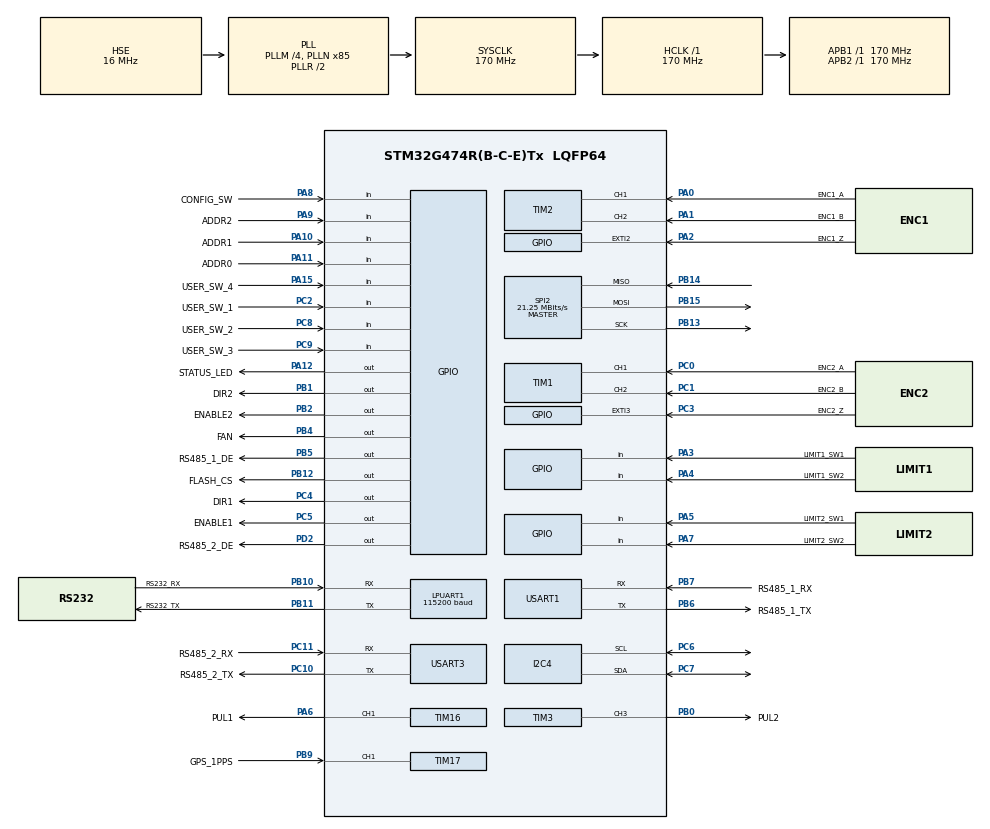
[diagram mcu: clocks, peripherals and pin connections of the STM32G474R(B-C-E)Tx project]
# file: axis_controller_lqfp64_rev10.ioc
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I2C4.Timing=0x40B285C2
LPUART1.BaudRate=115200
LPUART1.VirtualMode-Asynchronous=VM_ASYNC
Mcu.Family=STM32G4
Mcu.Name=STM32G474R(B-C-E)Tx
Mcu.Package=LQFP64
NVIC.EXTI2_IRQn=true\:0\:0\:false\:false\:true\:true\:true\:true
NVIC.EXTI3_IRQn=true\:0\:0\:false\:false\:true\:true\:true\:true
NVIC.I2C4_EV_IRQn=true\:0\:0\:false\:false\:true\:true\:true\:true
NVIC.LPUART1_IRQn=true\:0\:0\:false\:false\:true\:true\:true\:true
NVIC.PriorityGroup=NVIC_PRIORITYGROUP_4
NVIC.SPI2_IRQn=true\:0\:0\:false\:false\:true\:true\:true\:true
NVIC.TIM1_CC_IRQn=true\:0\:0\:false\:false\:true\:true\:true\:true
NVIC.TIM1_TRG_COM_TIM17_IRQn=true\:0\:0\:false\:false\:true\:true\:true\:true
NVIC.TIM1_UP_TIM16_IRQn=true\:0\:0\:false\:false\:true\:true\:true\:true
NVIC.TIM2_IRQn=true\:0\:0\:false\:false\:true\:true\:true\:true
NVIC.TIM3_IRQn=true\:0\:0\:false\:false\:true\:true\:true\:true
NVIC.USART1_IRQn=true\:0\:0\:false\:false\:true\:true\:true\:true
NVIC.USART3_IRQn=true\:0\:0\:false\:false\:true\:true\:true\:true
PA0.GPIO_Label=ENC1_A
PA0.Signal=S_TIM2_CH1
PA1.GPIO_Label=ENC1_B
PA1.Signal=S_TIM2_CH2
PA10.GPIO_Label=ADDR1
PA10.GPIO_PuPd=GPIO_PULLUP
PA10.Signal=GPIO_Input
PA11.GPIO_Label=ADDR0
PA11.GPIO_PuPd=GPIO_PULLUP
PA11.Signal=GPIO_Input
PA12.GPIO_Label=STATUS_LED
PA12.Signal=GPIO_Output
PA13.Mode=Trace_Asynchronous_SW
PA13.Signal=SYS_JTMS-SWDIO
PA14.Mode=Trace_Asynchronous_SW
PA14.Signal=SYS_JTCK-SWCLK
PA15.GPIO_Label=USER_SW_4
PA15.GPIO_PuPd=GPIO_PULLUP
PA15.Signal=GPIO_Input
PA2.GPIO_Label=ENC1_Z
PA2.GPIO_PuPd=GPIO_PULLUP
PA2.Signal=GPXTI2
PA3.GPIO_Label=LIMIT1_SW1
PA3.GPIO_PuPd=GPIO_PULLUP
PA3.Signal=GPIO_Input
PA4.GPIO_Label=LIMIT1_SW2
PA4.GPIO_PuPd=GPIO_PULLUP
PA4.Signal=GPIO_Input
PA5.GPIO_Label=LIMIT2_SW1
PA5.GPIO_PuPd=GPIO_PULLUP
PA5.Signal=GPIO_Input
PA6.GPIO_Label=PUL1
PA6.Signal=S_TIM16_CH1
PA7.GPIO_Label=LIMIT2_SW2
PA7.GPIO_PuPd=GPIO_PULLUP
PA7.Signal=GPIO_Input
PA8.GPIO_Label=CONFIG_SW
PA8.GPIO_PuPd=GPIO_PULLUP
PA8.Signal=GPIO_Input
PA9.GPIO_Label=ADDR2
PA9.GPIO_PuPd=GPIO_PULLUP
PA9.Signal=GPIO_Input
PB0.GPIO_Label=PUL2
PB0.Signal=S_TIM3_CH3
PB1.GPIO_Label=DIR2
PB1.Signal=GPIO_Output
PB10.GPIO_Label=RS232_RX
PB10.Mode=Asynchronous
PB10.Signal=LPUART1_RX
PB11.GPIO_Label=RS232_TX
PB11.Mode=Asynchronous
PB11.Signal=LPUART1_TX
PB12.GPIO_Label=FLASH_CS
PB12.GPIO_ModeDefaultOutputPP=GPIO_MODE_OUTPUT_PP
PB12.GPIO_Speed=GPIO_SPEED_FREQ_HIGH
PB12.Signal=GPIO_Output
PB13.Mode=Full_Duplex_Master
PB13.Signal=SPI2_SCK
PB14.Mode=Full_Duplex_Master
PB14.Signal=SPI2_MISO
PB15.Mode=Full_Duplex_Master
PB15.Signal=SPI2_MOSI
PB2.GPIO_Label=ENABLE2
PB2.Signal=GPIO_Output
PB3.Mode=Trace_Asynchronous_SW
PB3.Signal=SYS_JTDO-SWO
PB4.GPIO_Label=FAN
PB4.Signal=GPIO_Output
PB5.GPIO_Label=RS485_1_DE
PB5.Signal=GPIO_Output
PB6.GPIO_Label=RS485_1_TX
PB6.Mode=Asynchronous
PB6.Signal=USART1_TX
PB7.GPIO_Label=RS485_1_RX
PB7.Mode=Asynchronous
PB7.Signal=USART1_RX
PB9.GPIO_Label=GPS_1PPS
PB9.Signal=S_TIM17_CH1
PC0.GPIO_Label=ENC2_A
PC0.Signal=S_TIM1_CH1
PC1.GPIO_Label=ENC2_B
PC1.Signal=S_TIM1_CH2
PC10.GPIO_Label=RS485_2_TX
PC10.Mode=Asynchronous
PC10.Signal=USART3_TX
PC11.GPIO_Label=RS485_2_RX
PC11.Mode=Asynchronous
PC11.Signal=USART3_RX
PC2.GPIO_Label=USER_SW_1
PC2.GPIO_PuPd=GPIO_PULLUP
PC2.Signal=GPIO_Input
PC3.GPIO_Label=ENC2_Z
PC3.GPIO_PuPd=GPIO_PULLUP
PC3.Signal=GPXTI3
PC4.GPIO_Label=DIR1
PC4.Signal=GPIO_Output
PC5.GPIO_Label=ENABLE1
PC5.Signal=GPIO_Output
PC6.Mode=I2C
PC6.Signal=I2C4_SCL
PC7.Mode=I2C
PC7.Signal=I2C4_SDA
PC8.GPIO_Label=USER_SW_2
PC8.GPIO_PuPd=GPIO_PULLUP
PC8.Signal=GPIO_Input
PC9.GPIO_Label=USER_SW_3
PC9.GPIO_PuPd=GPIO_PULLUP
PC9.Signal=GPIO_Input
PD2.GPIO_Label=RS485_2_DE
PD2.Signal=GPIO_Output
PF0-OSC_IN.Mode=HSE-External-Oscillator
PF0-OSC_IN.Signal=RCC_OSC_IN
PF1-OSC_OUT.Mode=HSE-External-Oscillator
PF1-OSC_OUT.Signal=RCC_OSC_OUT
ProjectManager.HeapSize=0x800
ProjectManager.StackSize=0x800
ProjectManager.TargetToolchain=Makefile
RCC.ADC12Freq_Value=170000000
RCC.ADC345Freq_Value=170000000
RCC.AHBFreq_Value=170000000
RCC.APB1Freq_Value=170000000
RCC.APB1TimFreq_Value=170000000
RCC.APB2Freq_Value=170000000
RCC.APB2TimFreq_Value=170000000
RCC.CortexFreq_Value=170000000
RCC.EXTERNAL_CLOCK_VALUE=12288000
RCC.HCLKFreq_Value=170000000
RCC.HSE_VALUE=16000000
RCC.HSI48_VALUE=48000000
RCC.HSI_VALUE=16000000
RCC.LSE_VALUE=32768
RCC.PLLM=RCC_PLLM_DIV4
RCC.PLLN=85
RCC.PLLSourceVirtual=RCC_PLLSOURCE_HSE
RCC.SYSCLKFreq_VALUE=170000000
RCC.SYSCLKSource=RCC_SYSCLKSOURCE_PLLCLK
RCC.USBFreq_Value=170000000
RCC.VCOOutputFreq_Value=340000000
SH.S_TIM16_CH1.0=TIM16_CH1,PWM Generation1 CH1
SH.S_TIM17_CH1.0=TIM17_CH1,Input_Capture1_from_TI1
SH.S_TIM1_CH1.0=TIM1_CH1,Encoder_Interface
SH.S_TIM1_CH2.0=TIM1_CH2,Encoder_Interface
SH.S_TIM2_CH1.0=TIM2_CH1,Encoder_Interface
SH.S_TIM2_CH2.0=TIM2_CH2,Encoder_Interface
SH.S_TIM3_CH3.0=TIM3_CH3,PWM Generation3 CH3
SPI2.BaudRatePrescaler=SPI_BAUDRATEPRESCALER_8
SPI2.CLKPhase=SPI_PHASE_1EDGE
SPI2.CLKPolarity=SPI_POLARITY_LOW
SPI2.CalculateBaudRate=21.25 MBits/s
SPI2.DataSize=SPI_DATASIZE_8BIT
SPI2.Direction=SPI_DIRECTION_2LINES
SPI2.FirstBit=SPI_FIRSTBIT_MSB
SPI2.Mode=SPI_MODE_MASTER
SPI2.NSS=SPI_NSS_SOFT
SPI2.VirtualMode-Full_Duplex_Master=VM_MASTER
SPI2.VirtualType=VM_MASTER
TIM1.EncoderMode=TIM_ENCODERMODE_TI12
TIM1.IC1Filter=6
TIM1.IC2Filter=6
TIM16.AutoReloadPreload=TIM_AUTORELOAD_PRELOAD_ENABLE
TIM16.Channel=TIM_CHANNEL_1
TIM16.PeriodNoDither=999
TIM16.Prescaler=16
TIM16.PulseNoDither_1=500
TIM17.Channel=TIM_CHANNEL_1
TIM2.EncoderMode=TIM_ENCODERMODE_TI12
TIM2.IC1Filter=6
TIM2.IC2Filter=6
TIM3.AutoReloadPreload=TIM_AUTORELOAD_PRELOAD_ENABLE
TIM3.Channel-PWM\ Generation3\ CH3=TIM_CHANNEL_3
TIM3.PeriodNoDither=999
TIM3.Prescaler=16
TIM3.PulseNoDither_3=500
USART1.VirtualMode-Asynchronous=VM_ASYNC
USART3.VirtualMode-Asynchronous=VM_ASYNC
VP_SYS_VS_DBSignals.Mode=DisableDeadBatterySignals
VP_TIM16_VS_ClockSourceINT.Mode=Enable_Timer
VP_TIM17_VS_ClockSourceINT.Mode=Enable_Timer
board=custom

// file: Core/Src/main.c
/* USER CODE BEGIN Header */
/**
  ******************************************************************************
  * @file           : main.c
  * @brief          : Main program body
  ******************************************************************************
  * @attention
  *
  * Copyright (c) 2026 STMicroelectronics.
  * All rights reserved.
  *
  * This software is licensed under terms that can be found in the LICENSE file
  * in the root directory of this software component.
  * If no LICENSE file comes with this software, it is provided AS-IS.
  *
  ******************************************************************************
  */
/* USER CODE END Header */
#include "main.h"

/* USER CODE BEGIN Includes */
#include "app.h"
/* USER CODE END Includes */

I2C_HandleTypeDef hi2c4;

UART_HandleTypeDef hlpuart1;
UART_HandleTypeDef huart1;
UART_HandleTypeDef huart3;

SPI_HandleTypeDef hspi2;

TIM_HandleTypeDef htim1;
TIM_HandleTypeDef htim2;
TIM_HandleTypeDef htim3;
TIM_HandleTypeDef htim16;
TIM_HandleTypeDef htim17;

void SystemClock_Config(void);
static void MX_GPIO_Init(void);
static void MX_I2C4_Init(void);
static void MX_LPUART1_UART_Init(void);
static void MX_USART1_UART_Init(void);
static void MX_USART3_UART_Init(void);
static void MX_SPI2_Init(void);
static void MX_TIM1_Init(void);
static void MX_TIM2_Init(void);
static void MX_TIM3_Init(void);
static void MX_TIM16_Init(void);
static void MX_TIM17_Init(void);

/* USER CODE BEGIN 0 */
#include <stdio.h>

int _write(int file, char *ptr, int len)
{
    for (int i = 0; i < len; i++)
    {
        /* ITM_SendChar() blocks forever on ITM->PORT[0] if nothing is
         * capturing SWO. Bound the wait so boot never hangs when no
         * debugger/trace tool is attached. */
        if ((ITM->TCR & ITM_TCR_ITMENA_Msk) && (ITM->TER & 1UL))
        {
            uint32_t timeout = 10000;
            while (ITM->PORT[0].u32 == 0UL && --timeout) { }
            if (timeout)
                ITM->PORT[0].u8 = (uint8_t)ptr[i];
        }
    }
    return len;
}
/* USER CODE END 0 */

int main(void)
{

  /* MCU Configuration--------------------------------------------------------*/

  /* Reset of all peripherals, Initializes the Flash interface and the Systick. */
  HAL_Init();

  /* Configure the system clock */
  SystemClock_Config();

  /* Initialize all configured peripherals */
  MX_GPIO_Init();
  MX_I2C4_Init();
  MX_LPUART1_UART_Init();
  MX_USART1_UART_Init();
  MX_USART3_UART_Init();
  MX_SPI2_Init();
  MX_TIM1_Init();
  MX_TIM2_Init();
  MX_TIM3_Init();
  MX_TIM16_Init();
  MX_TIM17_Init();
  /* USER CODE BEGIN 2 */
  App_Init();
  /* USER CODE END 2 */

  /* Infinite loop */
  /* USER CODE BEGIN WHILE */
  while (1)
  {
    App_Run();
    /* USER CODE END WHILE */

  }
}

void SystemClock_Config(void)
{
  RCC_OscInitTypeDef RCC_OscInitStruct = {0};
  RCC_ClkInitTypeDef RCC_ClkInitStruct = {0};

  /** Configure the main internal regulator output voltage
  */
  HAL_PWREx_ControlVoltageScaling(PWR_REGULATOR_VOLTAGE_SCALE1_BOOST);

  /** Initializes the RCC Oscillators according to the specified parameters
  * in the RCC_OscInitTypeDef structure.
  */
  RCC_OscInitStruct.OscillatorType = RCC_OSCILLATORTYPE_HSE;
  RCC_OscInitStruct.HSEState = RCC_HSE_ON;
  RCC_OscInitStruct.PLL.PLLState = RCC_PLL_ON;
  RCC_OscInitStruct.PLL.PLLSource = RCC_PLLSOURCE_HSE;
  RCC_OscInitStruct.PLL.PLLM = RCC_PLLM_DIV4;
  RCC_OscInitStruct.PLL.PLLN = 85;
  RCC_OscInitStruct.PLL.PLLP = RCC_PLLP_DIV2;
  RCC_OscInitStruct.PLL.PLLQ = RCC_PLLQ_DIV2;
  RCC_OscInitStruct.PLL.PLLR = RCC_PLLR_DIV2;
  if (HAL_RCC_OscConfig(&RCC_OscInitStruct) != HAL_OK)
  {
    Error_Handler();
  }

  /** Initializes the CPU, AHB and APB buses clocks
  */
  RCC_ClkInitStruct.ClockType = RCC_CLOCKTYPE_HCLK|RCC_CLOCKTYPE_SYSCLK
                              |RCC_CLOCKTYPE_PCLK1|RCC_CLOCKTYPE_PCLK2;
  RCC_ClkInitStruct.SYSCLKSource = RCC_SYSCLKSOURCE_PLLCLK;
  RCC_ClkInitStruct.AHBCLKDivider = RCC_SYSCLK_DIV1;
  RCC_ClkInitStruct.APB1CLKDivider = RCC_HCLK_DIV1;
  RCC_ClkInitStruct.APB2CLKDivider = RCC_HCLK_DIV1;

  if (HAL_RCC_ClockConfig(&RCC_ClkInitStruct, FLASH_LATENCY_4) != HAL_OK)
  {
    Error_Handler();
  }
}

static void MX_I2C4_Init(void)
{

  hi2c4.Instance = I2C4;
  hi2c4.Init.Timing = 0x40B285C2;
  hi2c4.Init.OwnAddress1 = 0;
  hi2c4.Init.AddressingMode = I2C_ADDRESSINGMODE_7BIT;
  hi2c4.Init.DualAddressMode = I2C_DUALADDRESS_DISABLE;
  hi2c4.Init.OwnAddress2 = 0;
  hi2c4.Init.OwnAddress2Masks = I2C_OA2_NOMASK;
  hi2c4.Init.GeneralCallMode = I2C_GENERALCALL_DISABLE;
  hi2c4.Init.NoStretchMode = I2C_NOSTRETCH_DISABLE;
  if (HAL_I2C_Init(&hi2c4) != HAL_OK)
  {
    Error_Handler();
  }

  /** Configure Analogue filter
  */
  if (HAL_I2CEx_ConfigAnalogFilter(&hi2c4, I2C_ANALOGFILTER_ENABLE) != HAL_OK)
  {
    Error_Handler();
  }

  /** Configure Digital filter
  */
  if (HAL_I2CEx_ConfigDigitalFilter(&hi2c4, 0) != HAL_OK)
  {
    Error_Handler();
  }

}

static void MX_LPUART1_UART_Init(void)
{

  hlpuart1.Instance = LPUART1;
  hlpuart1.Init.BaudRate = 115200;
  hlpuart1.Init.WordLength = UART_WORDLENGTH_8B;
  hlpuart1.Init.StopBits = UART_STOPBITS_1;
  hlpuart1.Init.Parity = UART_PARITY_NONE;
  hlpuart1.Init.Mode = UART_MODE_TX_RX;
  hlpuart1.Init.HwFlowCtl = UART_HWCONTROL_NONE;
  hlpuart1.Init.OneBitSampling = UART_ONE_BIT_SAMPLE_DISABLE;
  hlpuart1.Init.ClockPrescaler = UART_PRESCALER_DIV1;
  hlpuart1.AdvancedInit.AdvFeatureInit = UART_ADVFEATURE_NO_INIT;
  if (HAL_UART_Init(&hlpuart1) != HAL_OK)
  {
    Error_Handler();
  }
  if (HAL_UARTEx_SetTxFifoThreshold(&hlpuart1, UART_TXFIFO_THRESHOLD_1_8) != HAL_OK)
  {
    Error_Handler();
  }
  if (HAL_UARTEx_SetRxFifoThreshold(&hlpuart1, UART_RXFIFO_THRESHOLD_1_8) != HAL_OK)
  {
    Error_Handler();
  }
  if (HAL_UARTEx_DisableFifoMode(&hlpuart1) != HAL_OK)
  {
    Error_Handler();
  }

}

static void MX_USART1_UART_Init(void)
{

  huart1.Instance = USART1;
  huart1.Init.BaudRate = 115200;
  huart1.Init.WordLength = UART_WORDLENGTH_8B;
  huart1.Init.StopBits = UART_STOPBITS_1;
  huart1.Init.Parity = UART_PARITY_NONE;
  huart1.Init.Mode = UART_MODE_TX_RX;
  huart1.Init.HwFlowCtl = UART_HWCONTROL_NONE;
  huart1.Init.OverSampling = UART_OVERSAMPLING_16;
  huart1.Init.OneBitSampling = UART_ONE_BIT_SAMPLE_DISABLE;
  huart1.Init.ClockPrescaler = UART_PRESCALER_DIV1;
  huart1.AdvancedInit.AdvFeatureInit = UART_ADVFEATURE_NO_INIT;
  if (HAL_UART_Init(&huart1) != HAL_OK)
  {
    Error_Handler();
  }
  if (HAL_UARTEx_SetTxFifoThreshold(&huart1, UART_TXFIFO_THRESHOLD_1_8) != HAL_OK)
  {
    Error_Handler();
  }
  if (HAL_UARTEx_SetRxFifoThreshold(&huart1, UART_RXFIFO_THRESHOLD_1_8) != HAL_OK)
  {
    Error_Handler();
  }
  if (HAL_UARTEx_DisableFifoMode(&huart1) != HAL_OK)
  {
    Error_Handler();
  }

}

static void MX_USART3_UART_Init(void)
{

  huart3.Instance = USART3;
  huart3.Init.BaudRate = 115200;
  huart3.Init.WordLength = UART_WORDLENGTH_8B;
  huart3.Init.StopBits = UART_STOPBITS_1;
  huart3.Init.Parity = UART_PARITY_NONE;
  huart3.Init.Mode = UART_MODE_TX_RX;
  huart3.Init.HwFlowCtl = UART_HWCONTROL_NONE;
  huart3.Init.OverSampling = UART_OVERSAMPLING_16;
  huart3.Init.OneBitSampling = UART_ONE_BIT_SAMPLE_DISABLE;
  huart3.Init.ClockPrescaler = UART_PRESCALER_DIV1;
  huart3.AdvancedInit.AdvFeatureInit = UART_ADVFEATURE_NO_INIT;
  if (HAL_UART_Init(&huart3) != HAL_OK)
  {
    Error_Handler();
  }
  if (HAL_UARTEx_SetTxFifoThreshold(&huart3, UART_TXFIFO_THRESHOLD_1_8) != HAL_OK)
  {
    Error_Handler();
  }
  if (HAL_UARTEx_SetRxFifoThreshold(&huart3, UART_RXFIFO_THRESHOLD_1_8) != HAL_OK)
  {
    Error_Handler();
  }
  if (HAL_UARTEx_DisableFifoMode(&huart3) != HAL_OK)
  {
    Error_Handler();
  }

}

static void MX_SPI2_Init(void)
{

  /* SPI2 parameter configuration*/
  hspi2.Instance = SPI2;
  hspi2.Init.Mode = SPI_MODE_MASTER;
  hspi2.Init.Direction = SPI_DIRECTION_2LINES;
  hspi2.Init.DataSize = SPI_DATASIZE_8BIT;
  hspi2.Init.CLKPolarity = SPI_POLARITY_LOW;
  hspi2.Init.CLKPhase = SPI_PHASE_1EDGE;
  hspi2.Init.NSS = SPI_NSS_SOFT;
  hspi2.Init.BaudRatePrescaler = SPI_BAUDRATEPRESCALER_8;
  hspi2.Init.FirstBit = SPI_FIRSTBIT_MSB;
  hspi2.Init.TIMode = SPI_TIMODE_DISABLE;
  hspi2.Init.CRCCalculation = SPI_CRCCALCULATION_DISABLE;
  hspi2.Init.CRCPolynomial = 7;
  hspi2.Init.CRCLength = SPI_CRC_LENGTH_DATASIZE;
  hspi2.Init.NSSPMode = SPI_NSS_PULSE_ENABLE;
  if (HAL_SPI_Init(&hspi2) != HAL_OK)
  {
    Error_Handler();
  }

}

static void MX_TIM1_Init(void)
{

  TIM_Encoder_InitTypeDef sConfig = {0};
  TIM_MasterConfigTypeDef sMasterConfig = {0};

  htim1.Instance = TIM1;
  htim1.Init.Prescaler = 0;
  htim1.Init.CounterMode = TIM_COUNTERMODE_UP;
  htim1.Init.Period = 65535;
  htim1.Init.ClockDivision = TIM_CLOCKDIVISION_DIV1;
  htim1.Init.RepetitionCounter = 0;
  htim1.Init.AutoReloadPreload = TIM_AUTORELOAD_PRELOAD_DISABLE;
  sConfig.EncoderMode = TIM_ENCODERMODE_TI12;
  sConfig.IC1Polarity = TIM_ICPOLARITY_RISING;
  sConfig.IC1Selection = TIM_ICSELECTION_DIRECTTI;
  sConfig.IC1Prescaler = TIM_ICPSC_DIV1;
  sConfig.IC1Filter = 6;
  sConfig.IC2Polarity = TIM_ICPOLARITY_RISING;
  sConfig.IC2Selection = TIM_ICSELECTION_DIRECTTI;
  sConfig.IC2Prescaler = TIM_ICPSC_DIV1;
  sConfig.IC2Filter = 6;
  if (HAL_TIM_Encoder_Init(&htim1, &sConfig) != HAL_OK)
  {
    Error_Handler();
  }
  sMasterConfig.MasterOutputTrigger = TIM_TRGO_RESET;
  sMasterConfig.MasterOutputTrigger2 = TIM_TRGO2_RESET;
  sMasterConfig.MasterSlaveMode = TIM_MASTERSLAVEMODE_DISABLE;
  if (HAL_TIMEx_MasterConfigSynchronization(&htim1, &sMasterConfig) != HAL_OK)
  {
    Error_Handler();
  }

}

static void MX_TIM2_Init(void)
{

  TIM_Encoder_InitTypeDef sConfig = {0};
  TIM_MasterConfigTypeDef sMasterConfig = {0};

  htim2.Instance = TIM2;
  htim2.Init.Prescaler = 0;
  htim2.Init.CounterMode = TIM_COUNTERMODE_UP;
  htim2.Init.Period = 4294967295;
  htim2.Init.ClockDivision = TIM_CLOCKDIVISION_DIV1;
  htim2.Init.AutoReloadPreload = TIM_AUTORELOAD_PRELOAD_DISABLE;
  sConfig.EncoderMode = TIM_ENCODERMODE_TI12;
  sConfig.IC1Polarity = TIM_ICPOLARITY_RISING;
  sConfig.IC1Selection = TIM_ICSELECTION_DIRECTTI;
  sConfig.IC1Prescaler = TIM_ICPSC_DIV1;
  sConfig.IC1Filter = 6;
  sConfig.IC2Polarity = TIM_ICPOLARITY_RISING;
  sConfig.IC2Selection = TIM_ICSELECTION_DIRECTTI;
  sConfig.IC2Prescaler = TIM_ICPSC_DIV1;
  sConfig.IC2Filter = 6;
  if (HAL_TIM_Encoder_Init(&htim2, &sConfig) != HAL_OK)
  {
    Error_Handler();
  }
  sMasterConfig.MasterOutputTrigger = TIM_TRGO_RESET;
  sMasterConfig.MasterSlaveMode = TIM_MASTERSLAVEMODE_DISABLE;
  if (HAL_TIMEx_MasterConfigSynchronization(&htim2, &sMasterConfig) != HAL_OK)
  {
    Error_Handler();
  }

}

static void MX_TIM3_Init(void)
{

  TIM_MasterConfigTypeDef sMasterConfig = {0};
  TIM_OC_InitTypeDef sConfigOC = {0};

  htim3.Instance = TIM3;
  htim3.Init.Prescaler = 16;
  htim3.Init.CounterMode = TIM_COUNTERMODE_UP;
  htim3.Init.Period = 999;
  htim3.Init.ClockDivision = TIM_CLOCKDIVISION_DIV1;
  htim3.Init.AutoReloadPreload = TIM_AUTORELOAD_PRELOAD_ENABLE;
  if (HAL_TIM_PWM_Init(&htim3) != HAL_OK)
  {
    Error_Handler();
  }
  sMasterConfig.MasterOutputTrigger = TIM_TRGO_RESET;
  sMasterConfig.MasterSlaveMode = TIM_MASTERSLAVEMODE_DISABLE;
  if (HAL_TIMEx_MasterConfigSynchronization(&htim3, &sMasterConfig) != HAL_OK)
  {
    Error_Handler();
  }
  sConfigOC.OCMode = TIM_OCMODE_PWM1;
  sConfigOC.Pulse = 500;
  sConfigOC.OCPolarity = TIM_OCPOLARITY_HIGH;
  sConfigOC.OCFastMode = TIM_OCFAST_DISABLE;
  if (HAL_TIM_PWM_ConfigChannel(&htim3, &sConfigOC, TIM_CHANNEL_3) != HAL_OK)
  {
    Error_Handler();
  }
  HAL_TIM_MspPostInit(&htim3);

}

static void MX_TIM16_Init(void)
{

  TIM_OC_InitTypeDef sConfigOC = {0};
  TIM_BreakDeadTimeConfigTypeDef sBreakDeadTimeConfig = {0};

  htim16.Instance = TIM16;
  htim16.Init.Prescaler = 16;
  htim16.Init.CounterMode = TIM_COUNTERMODE_UP;
  htim16.Init.Period = 999;
  htim16.Init.ClockDivision = TIM_CLOCKDIVISION_DIV1;
  htim16.Init.RepetitionCounter = 0;
  htim16.Init.AutoReloadPreload = TIM_AUTORELOAD_PRELOAD_ENABLE;
  if (HAL_TIM_Base_Init(&htim16) != HAL_OK)
  {
    Error_Handler();
  }
  if (HAL_TIM_PWM_Init(&htim16) != HAL_OK)
  {
    Error_Handler();
  }
  sConfigOC.OCMode = TIM_OCMODE_PWM1;
  sConfigOC.Pulse = 500;
  sConfigOC.OCPolarity = TIM_OCPOLARITY_HIGH;
  sConfigOC.OCNPolarity = TIM_OCNPOLARITY_HIGH;
  sConfigOC.OCFastMode = TIM_OCFAST_DISABLE;
  sConfigOC.OCIdleState = TIM_OCIDLESTATE_RESET;
  sConfigOC.OCNIdleState = TIM_OCNIDLESTATE_RESET;
  if (HAL_TIM_PWM_ConfigChannel(&htim16, &sConfigOC, TIM_CHANNEL_1) != HAL_OK)
  {
    Error_Handler();
  }
  sBreakDeadTimeConfig.OffStateRunMode = TIM_OSSR_DISABLE;
  sBreakDeadTimeConfig.OffStateIDLEMode = TIM_OSSI_DISABLE;
  sBreakDeadTimeConfig.LockLevel = TIM_LOCKLEVEL_OFF;
  sBreakDeadTimeConfig.DeadTime = 0;
  sBreakDeadTimeConfig.BreakState = TIM_BREAK_DISABLE;
  sBreakDeadTimeConfig.BreakPolarity = TIM_BREAKPOLARITY_HIGH;
  sBreakDeadTimeConfig.BreakFilter = 0;
  sBreakDeadTimeConfig.AutomaticOutput = TIM_AUTOMATICOUTPUT_DISABLE;
  if (HAL_TIMEx_ConfigBreakDeadTime(&htim16, &sBreakDeadTimeConfig) != HAL_OK)
  {
    Error_Handler();
  }
  HAL_TIM_MspPostInit(&htim16);

}

static void MX_TIM17_Init(void)
{

  TIM_IC_InitTypeDef sConfigIC = {0};

  htim17.Instance = TIM17;
  htim17.Init.Prescaler = 0;
  htim17.Init.CounterMode = TIM_COUNTERMODE_UP;
  htim17.Init.Period = 65535;
  htim17.Init.ClockDivision = TIM_CLOCKDIVISION_DIV1;
  htim17.Init.RepetitionCounter = 0;
  htim17.Init.AutoReloadPreload = TIM_AUTORELOAD_PRELOAD_DISABLE;
  if (HAL_TIM_Base_Init(&htim17) != HAL_OK)
  {
    Error_Handler();
  }
  if (HAL_TIM_IC_Init(&htim17) != HAL_OK)
  {
    Error_Handler();
  }
  sConfigIC.ICPolarity = TIM_INPUTCHANNELPOLARITY_RISING;
  sConfigIC.ICSelection = TIM_ICSELECTION_DIRECTTI;
  sConfigIC.ICPrescaler = TIM_ICPSC_DIV1;
  sConfigIC.ICFilter = 0;
  if (HAL_TIM_IC_ConfigChannel(&htim17, &sConfigIC, TIM_CHANNEL_1) != HAL_OK)
  {
    Error_Handler();
  }

}

static void MX_GPIO_Init(void)
{
  GPIO_InitTypeDef GPIO_InitStruct = {0};

  /* GPIO Ports Clock Enable */
  __HAL_RCC_GPIOF_CLK_ENABLE();
  __HAL_RCC_GPIOC_CLK_ENABLE();
  __HAL_RCC_GPIOA_CLK_ENABLE();
  __HAL_RCC_GPIOB_CLK_ENABLE();
  __HAL_RCC_GPIOD_CLK_ENABLE();

  /*Configure GPIO pin Output Level */
  HAL_GPIO_WritePin(GPIOC, DIR1_Pin|ENABLE1_Pin, GPIO_PIN_RESET);

  /*Configure GPIO pin Output Level */
  HAL_GPIO_WritePin(GPIOB, DIR2_Pin|ENABLE2_Pin|FLASH_CS_Pin|FAN_Pin
                          |RS485_1_DE_Pin, GPIO_PIN_RESET);

  /*Configure GPIO pin Output Level */
  HAL_GPIO_WritePin(STATUS_LED_GPIO_Port, STATUS_LED_Pin, GPIO_PIN_RESET);

  /*Configure GPIO pin Output Level */
  HAL_GPIO_WritePin(RS485_2_DE_GPIO_Port, RS485_2_DE_Pin, GPIO_PIN_RESET);

  /*Configure GPIO pins : USER_SW_1_Pin USER_SW_2_Pin USER_SW_3_Pin */
  GPIO_InitStruct.Pin = USER_SW_1_Pin|USER_SW_2_Pin|USER_SW_3_Pin;
  GPIO_InitStruct.Mode = GPIO_MODE_INPUT;
  GPIO_InitStruct.Pull = GPIO_PULLUP;
  HAL_GPIO_Init(GPIOC, &GPIO_InitStruct);

  /*Configure GPIO pin : ENC2_Z_Pin */
  GPIO_InitStruct.Pin = ENC2_Z_Pin;
  GPIO_InitStruct.Mode = GPIO_MODE_IT_RISING;
  GPIO_InitStruct.Pull = GPIO_PULLUP;
  HAL_GPIO_Init(ENC2_Z_GPIO_Port, &GPIO_InitStruct);

  /*Configure GPIO pin : ENC1_Z_Pin */
  GPIO_InitStruct.Pin = ENC1_Z_Pin;
  GPIO_InitStruct.Mode = GPIO_MODE_IT_RISING;
  GPIO_InitStruct.Pull = GPIO_PULLUP;
  HAL_GPIO_Init(ENC1_Z_GPIO_Port, &GPIO_InitStruct);

  /*Configure GPIO pins : LIMIT1_SW1_Pin LIMIT1_SW2_Pin LIMIT2_SW1_Pin LIMIT2_SW2_Pin
                           CONFIG_SW_Pin ADDR2_Pin ADDR1_Pin ADDR0_Pin
                           USER_SW_4_Pin */
  GPIO_InitStruct.Pin = LIMIT1_SW1_Pin|LIMIT1_SW2_Pin|LIMIT2_SW1_Pin|LIMIT2_SW2_Pin
                          |CONFIG_SW_Pin|ADDR2_Pin|ADDR1_Pin|ADDR0_Pin
                          |USER_SW_4_Pin;
  GPIO_InitStruct.Mode = GPIO_MODE_INPUT;
  GPIO_InitStruct.Pull = GPIO_PULLUP;
  HAL_GPIO_Init(GPIOA, &GPIO_InitStruct);

  /*Configure GPIO pins : DIR1_Pin ENABLE1_Pin */
  GPIO_InitStruct.Pin = DIR1_Pin|ENABLE1_Pin;
  GPIO_InitStruct.Mode = GPIO_MODE_OUTPUT_PP;
  GPIO_InitStruct.Pull = GPIO_NOPULL;
  GPIO_InitStruct.Speed = GPIO_SPEED_FREQ_LOW;
  HAL_GPIO_Init(GPIOC, &GPIO_InitStruct);

  /*Configure GPIO pins : DIR2_Pin ENABLE2_Pin FAN_Pin RS485_1_DE_Pin */
  GPIO_InitStruct.Pin = DIR2_Pin|ENABLE2_Pin|FAN_Pin|RS485_1_DE_Pin;
  GPIO_InitStruct.Mode = GPIO_MODE_OUTPUT_PP;
  GPIO_InitStruct.Pull = GPIO_NOPULL;
  GPIO_InitStruct.Speed = GPIO_SPEED_FREQ_LOW;
  HAL_GPIO_Init(GPIOB, &GPIO_InitStruct);

  /*Configure GPIO pin : FLASH_CS_Pin */
  GPIO_InitStruct.Pin = FLASH_CS_Pin;
  GPIO_InitStruct.Mode = GPIO_MODE_OUTPUT_PP;
  GPIO_InitStruct.Pull = GPIO_NOPULL;
  GPIO_InitStruct.Speed = GPIO_SPEED_FREQ_HIGH;
  HAL_GPIO_Init(FLASH_CS_GPIO_Port, &GPIO_InitStruct);

  /*Configure GPIO pin : STATUS_LED_Pin */
  GPIO_InitStruct.Pin = STATUS_LED_Pin;
  GPIO_InitStruct.Mode = GPIO_MODE_OUTPUT_PP;
  GPIO_InitStruct.Pull = GPIO_NOPULL;
  GPIO_InitStruct.Speed = GPIO_SPEED_FREQ_LOW;
  HAL_GPIO_Init(STATUS_LED_GPIO_Port, &GPIO_InitStruct);

  /*Configure GPIO pin : RS485_2_DE_Pin */
  GPIO_InitStruct.Pin = RS485_2_DE_Pin;
  GPIO_InitStruct.Mode = GPIO_MODE_OUTPUT_PP;
  GPIO_InitStruct.Pull = GPIO_NOPULL;
  GPIO_InitStruct.Speed = GPIO_SPEED_FREQ_LOW;
  HAL_GPIO_Init(RS485_2_DE_GPIO_Port, &GPIO_InitStruct);

  /* EXTI interrupt init*/
  HAL_NVIC_SetPriority(EXTI2_IRQn, 0, 0);
  HAL_NVIC_EnableIRQ(EXTI2_IRQn);

  HAL_NVIC_SetPriority(EXTI3_IRQn, 0, 0);
  HAL_NVIC_EnableIRQ(EXTI3_IRQn);

}

void Error_Handler(void)
{
  __disable_irq();
  while (1)
  {
  }
}
